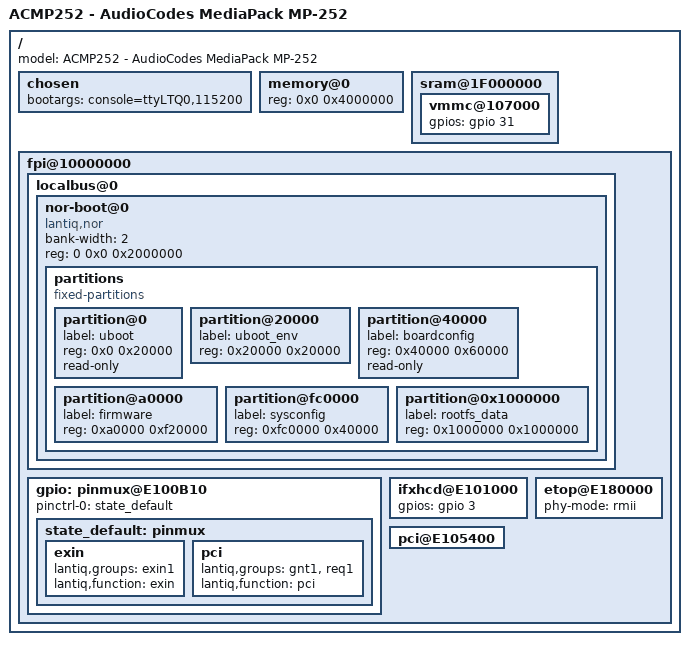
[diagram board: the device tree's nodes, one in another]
/dts-v1/;

#include "danube.dtsi"

/ {
	model = "ACMP252 - AudioCodes MediaPack MP-252";

	chosen {
		bootargs = "console=ttyLTQ0,115200";
	};

	memory@0 {
		reg = <0x0 0x4000000>;
	};

	sram@1F000000 {
		vmmc@107000 {
			status = "okay";
			gpios = <&gpio 31 GPIO_ACTIVE_HIGH>;
		};
	};

	fpi@10000000 {
		localbus@0 {
			nor-boot@0 {
				compatible = "lantiq,nor";
				bank-width = <2>;
				reg = <0 0x0 0x2000000>;
				#address-cells = <1>;
				#size-cells = <1>;

				partitions {
					compatible = "fixed-partitions";
					#address-cells = <1>;
					#size-cells = <1>;

					partition@0 {
						label = "uboot";
						reg = <0x0 0x20000>;
						read-only;
					};

					partition@20000 {
						label = "uboot_env";
						reg = <0x20000 0x20000>;
					};

					partition@40000 {
						label = "boardconfig";
						reg = <0x40000 0x60000>;
						read-only;
					};

					partition@a0000 {
						label = "firmware";
						reg = <0xa0000 0xf20000>;
					};

					partition@fc0000 {
						label = "sysconfig";
						reg = <0xfc0000 0x40000>;
					};

					partition@0x1000000 {
						label = "rootfs_data";
						reg = <0x1000000 0x1000000>;
					};
				};
			};
		};

		gpio: pinmux@E100B10 {
			pinctrl-names = "default";
			pinctrl-0 = <&state_default>;

			state_default: pinmux {
				exin {
					lantiq,groups = "exin1";
					lantiq,function = "exin";
				};
				pci {
					lantiq,groups = "gnt1", "req1";
					lantiq,function = "pci";
				};
			};
		};

		ifxhcd@E101000 {
			status = "okay";
			gpios = <&gpio 3 GPIO_ACTIVE_HIGH>;
		};

		etop@E180000 {
			phy-mode = "rmii";
		};

		pci@E105400 {
			status = "okay";
		};
	};
};
